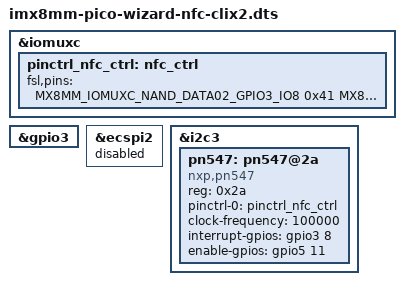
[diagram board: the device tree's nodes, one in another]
/*
 * Copyright 2018 Technexion Ltd.
 * Copyright 2018 NXP
 *
 * Author: Hank Chang <richard.hu@technexion.com>
 *
 * This program is free software; you can redistribute it and/or
 * modify it under the terms of the GNU General Public License
 * as published by the Free Software Foundation; either version 2
 * of the License, or (at your option) any later version.
 *
 * This program is distributed in the hope that it will be useful,
 * but WITHOUT ANY WARRANTY; without even the implied warranty of
 * MERCHANTABILITY or FITNESS FOR A PARTICULAR PURPOSE.  See the
 * GNU General Public License for more details.
 */

#include <dt-bindings/input/input.h>
#include "imx8mm-pico-wizard.dts"

&iomuxc {
	/* CLIX-7150 on CLIX1 interface */
	pinctrl_nfc_ctrl: nfc_ctrl {
		fsl,pins = <
			MX8MM_IOMUXC_NAND_DATA02_GPIO3_IO8	0x41	/* PIN_INT, GPIO_P32 */
			MX8MM_IOMUXC_ECSPI2_MOSI_GPIO5_IO11	0x41	/* PIN_ENABLE */
		>;
	};
};

/* NFC PIN_INT conflicts with GPIO_P32 */
&gpio3 {
	/delete-property/ pinctrl-names;
	/delete-property/ pinctrl-0;
	/delete-property/ gpio-line-names;
};

&ecspi2 {
	status = "disabled";
};

&i2c3 {
	pn547: pn547@2a {
		compatible = "nxp,pn547";
		reg = <0x2a>;
		pinctrl-names = "default";
		pinctrl-0 = <&pinctrl_nfc_ctrl>;
		clock-frequency = <100000>;
		interrupt-gpios = <&gpio3 8 0>;
		enable-gpios = <&gpio5 11 0>;
		status = "okay";
	};
};
